# STM32G070 register map
File version: 1.4
CPU: CM0 r0p1, little endian, MPU, no FPU, 2 interrupt priority bits
Registers are 32-bit, read-write, reset 0x0 unless marked. A register's access mark holds for its fields unless they carry their own. Offsets are from the block's base; [hi:lo] are bit positions; {n}, {i} and the like mark numbered series; 'fields as' and 'values as' point back to an identical list.

## TIM3 — General-purpose-timers
Base 0x40000400
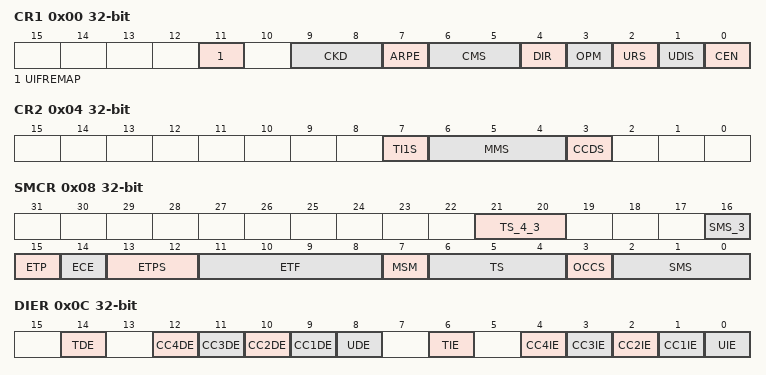
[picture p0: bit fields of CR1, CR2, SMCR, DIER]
0x00 CR1 — control register 1
  [11] UIFREMAP — UIF status bit remapping
  [9:8] CKD — Clock division
  [7] ARPE — Auto-reload preload enable
  [6:5] CMS — Center-aligned mode selection
  [4] DIR — Direction
  [3] OPM — One-pulse mode
  [2] URS — Update request source
  [1] UDIS — Update disable
  [0] CEN — Counter enable
0x04 CR2 — control register 2
  [7] TI1S — TI1 selection
  [6:4] MMS — Master mode selection
  [3] CCDS — Capture/compare DMA selection
0x08 SMCR — slave mode control register
  [21:20] TS_4_3 — Trigger selection
  [16] SMS_3 — Slave mode selection - bit 3
  [15] ETP — External trigger polarity
  [14] ECE — External clock enable
  [13:12] ETPS — External trigger prescaler
  [11:8] ETF — External trigger filter
  [7] MSM — Master/Slave mode
  [6:4] TS — Trigger selection
  [3] OCCS — OCREF clear selection
  [2:0] SMS — Slave mode selection
0x0C DIER — DMA/Interrupt enable register
  [14] TDE — Trigger DMA request enable
  [n+8] CC{n}DE (n=1..4) — Capture/Compare {n} DMA request enable
  [8] UDE — Update DMA request enable
  [6] TIE — Trigger interrupt enable
  [n] CC{n}IE (n=1..4) — Capture/Compare {n} interrupt enable
  [0] UIE — Update interrupt enable
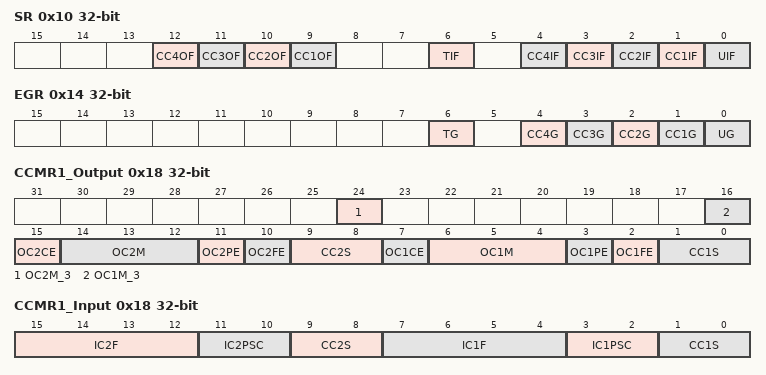
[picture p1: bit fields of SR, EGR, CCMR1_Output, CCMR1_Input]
0x10 SR — status register
  [12] CC4OF — Capture/Compare 4 overcapture flag
  [11] CC3OF — Capture/Compare 3 overcapture flag
  [10] CC2OF — Capture/compare 2 overcapture flag
  [9] CC1OF — Capture/Compare 1 overcapture flag
  [6] TIF — Trigger interrupt flag
  [4] CC4IF — Capture/Compare 4 interrupt flag
  [3] CC3IF — Capture/Compare 3 interrupt flag
  [2] CC2IF — Capture/Compare 2 interrupt flag
  [1] CC1IF — Capture/compare 1 interrupt flag
  [0] UIF — Update interrupt flag
0x14 EGR wo — event generation register
  [6] TG — Trigger generation
  [n] CC{n}G (n=1..4) — Capture/compare {n} generation
  [0] UG — Update generation
0x18 CCMR1_Output — capture/compare mode register 1 (output mode)
  [24] OC2M_3 — Output Compare 2 mode - bit 3
    0=Normal output compare mode (modes 0-7); 1=Extended output compare mode (modes 7-15)
  [16] OC1M_3 — Output Compare 1 mode - bit 3
    values as OC2M_3
  [15] OC2CE — Output compare 2 clear enable
  [14:12] OC2M — Output compare 2 mode
    0=Frozen (The comparison between the output compare register TIMx_CCRy and the counter TIMx_CNT has no effect on the outputs / OpmMode1: Retriggerable OPM mode 1 - In up-counting mode, the channel is active until a trigger event is detected (on TRGI signal). In down-counting mode, the channel is inactive); 1=ActiveOnMatch (Set channel to active level on match. OCyREF signal is forced high when the counter matches the capture/compare register / OpmMode2: Inversely to OpmMode1); 2=InactiveOnMatch (Set channel to inactive level on match. OCyREF signal is forced low when the counter matches the capture/compare register / Reserved); 3=Toggle (OCyREF toggles when TIMx_CNT=TIMx_CCRy / Reserved); 4=ForceInactive (OCyREF is forced low / CombinedPwmMode1: OCyREF has the same behavior as in PWM mode 1. OCyREFC is the logical OR between OC1REF and OC2REF); 5=ForceActive (OCyREF is forced high / CombinedPwmMode2: OCyREF has the same behavior as in PWM mode 2. OCyREFC is the logical AND between OC1REF and OC2REF); 6=PwmMode1 (In upcounting, channel is active as long as TIMx_CNT<TIMx_CCRy else inactive. In downcounting, channel is inactive as long as TIMx_CNT>TIMx_CCRy else active / AsymmetricPwmMode1: OCyREF has the same behavior as in PWM mode 1. OCyREFC outputs OC1REF when the counter is counting up, OC2REF when it is counting down); 7=PwmMode2 (Inversely to PwmMode1 / AsymmetricPwmMode2: Inversely to AsymmetricPwmMode1)
  [11] OC2PE — Output compare 2 preload enable
  [10] OC2FE — Output compare 2 fast enable
  [9:8] CC2S — Capture/Compare 2 selection
  [7] OC1CE — Output compare 1 clear enable
  [6:4] OC1M — Output compare 1 mode
    values as OC2M
  [3] OC1PE — Output compare 1 preload enable
  [2] OC1FE — Output compare 1 fast enable
  [1:0] CC1S — Capture/Compare 1 selection
0x18 CCMR1_Input (alternate view of CCMR1_Output) — capture/compare mode register 1 (input mode)
  [15:12] IC2F — Input capture 2 filter
  [11:10] IC2PSC — Input capture 2 prescaler
  [9:8] CC2S — Capture/compare 2 selection
  [7:4] IC1F — Input capture 1 filter
  [3:2] IC1PSC — Input capture 1 prescaler
  [1:0] CC1S — Capture/Compare 1 selection
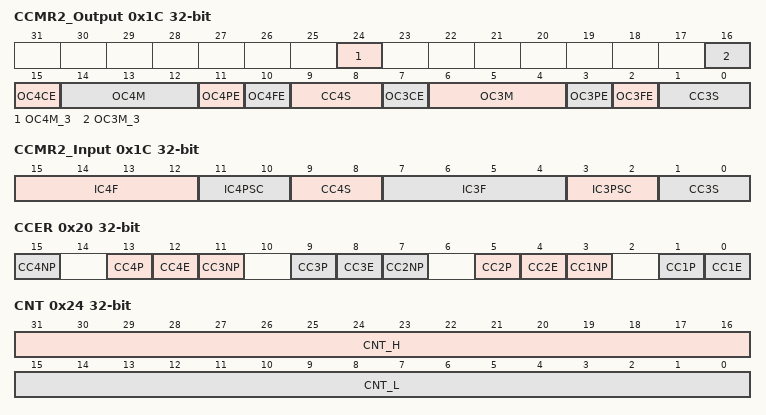
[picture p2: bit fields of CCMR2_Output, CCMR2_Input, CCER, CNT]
0x1C CCMR2_Output — capture/compare mode register 2 (output mode)
  [24] OC4M_3 — Output Compare 4 mode - bit 3
    values as CCMR1_Output.OC2M_3
  [16] OC3M_3 — Output Compare 3 mode - bit 3
    values as CCMR1_Output.OC2M_3
  [15] OC4CE — Output compare 4 clear enable
  [14:12] OC4M — Output compare 4 mode
    values as CCMR1_Output.OC2M
  [11] OC4PE — Output compare 4 preload enable
  [10] OC4FE — Output compare 4 fast enable
  [9:8] CC4S — Capture/Compare 4 selection
  [7] OC3CE — Output compare 3 clear enable
  [6:4] OC3M — Output compare 3 mode
    values as CCMR1_Output.OC2M
  [3] OC3PE — Output compare 3 preload enable
  [2] OC3FE — Output compare 3 fast enable
  [1:0] CC3S — Capture/Compare 3 selection
0x1C CCMR2_Input (alternate view of CCMR2_Output) — capture/compare mode register 2 (input mode)
  [15:12] IC4F — Input capture 4 filter
  [11:10] IC4PSC — Input capture 4 prescaler
  [9:8] CC4S — Capture/Compare 4 selection
  [7:4] IC3F — Input capture 3 filter
  [3:2] IC3PSC — Input capture 3 prescaler
  [1:0] CC3S — Capture/Compare 3 selection
0x20 CCER — capture/compare enable register
  [4n-1] CC{n}NP (n=1..4) — Capture/Compare {n} output Polarity
  [13] CC4P — Capture/Compare 3 output Polarity
  [4n-4] CC{n}E (n=1..4) — Capture/Compare {n} output enable
  [9] CC3P — Capture/Compare 3 output Polarity
  [5] CC2P — Capture/Compare 2 output Polarity
  [1] CC1P — Capture/Compare 1 output Polarity
0x24 CNT — counter
  [31:16] CNT_H — High counter value (TIM2 only)
  [15:0] CNT_L — Low counter value
0x28 PSC — prescaler
  [15:0] PSC — Prescaler value
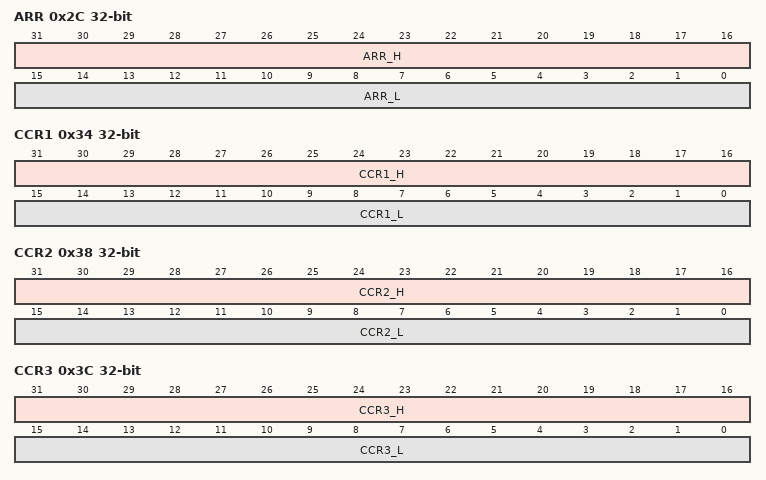
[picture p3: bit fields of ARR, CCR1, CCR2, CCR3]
0x2C ARR — auto-reload register
  [31:16] ARR_H — High Auto-reload value (TIM2 only)
  [15:0] ARR_L — Low Auto-reload value
0x34 CCR1 — capture/compare register 1
  [31:16] CCR1_H — High Capture/Compare 1 value (TIM2 only)
  [15:0] CCR1_L — Low Capture/Compare 1 value
0x38 CCR2 — capture/compare register 2
  [31:16] CCR2_H — High Capture/Compare 2 value (TIM2 only)
  [15:0] CCR2_L — Low Capture/Compare 2 value
0x3C CCR3 — capture/compare register 3
  [31:16] CCR3_H — High Capture/Compare value (TIM2 only)
  [15:0] CCR3_L — Low Capture/Compare value
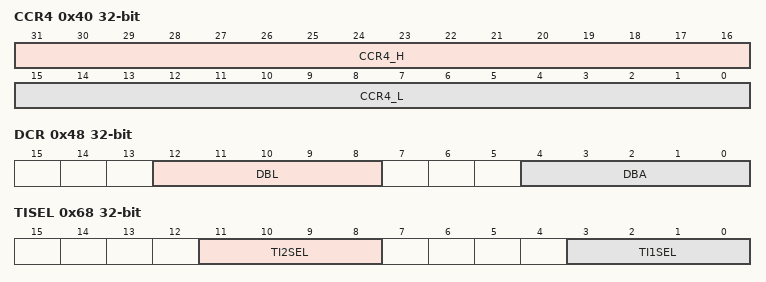
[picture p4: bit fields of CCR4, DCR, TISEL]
0x40 CCR4 — capture/compare register 4
  [31:16] CCR4_H — High Capture/Compare value (TIM2 only)
  [15:0] CCR4_L — Low Capture/Compare value
0x48 DCR — DMA control register
  [12:8] DBL — DMA burst length
  [4:0] DBA — DMA base address
0x4C DMAR — DMA address for full transfer
  [15:0] DMAB — DMA register for burst accesses
0x50 OR1 — TIM option register
  [0] IOCREF_CLR
0x60 AF1 — TIM alternate function option register 1
  [17:14] ETRSEL — External trigger source selection
0x68 TISEL — TIM alternate function option register 1
  [11:8] TI2SEL, [3:0] TI1SEL
